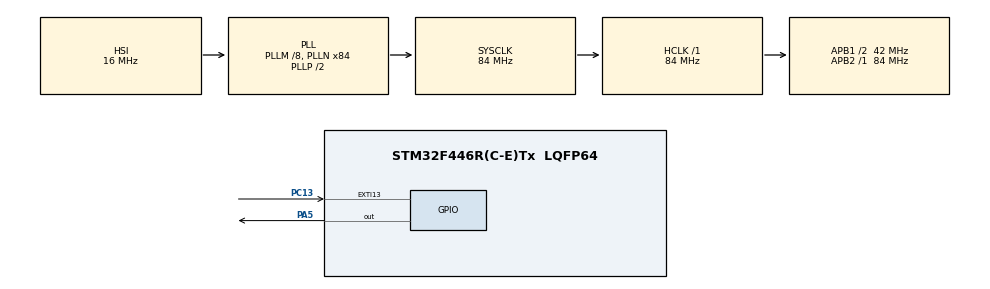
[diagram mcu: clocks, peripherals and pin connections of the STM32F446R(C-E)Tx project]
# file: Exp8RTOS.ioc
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FREERTOS.BinarySemaphores01=myBinarySem01,Dynamic,NULL,Available
FREERTOS.Tasks01=LED_Control,24,128,StartDefaultTask,Default,NULL,Dynamic,NULL,NULL
Mcu.Family=STM32F4
Mcu.Name=STM32F446R(C-E)Tx
Mcu.Package=LQFP64
NVIC.EXTI15_10_IRQn=true\:7\:0\:true\:false\:true\:true\:true\:true\:true
NVIC.PriorityGroup=NVIC_PRIORITYGROUP_4
NVIC.TIM6_DAC_IRQn=true\:15\:0\:false\:false\:true\:false\:false\:true\:true
NVIC.TimeBase=TIM6_DAC_IRQn
NVIC.TimeBaseIP=TIM6
PA13.Mode=Trace_Asynchronous_SW
PA13.Signal=SYS_JTMS-SWDIO
PA14.Mode=Trace_Asynchronous_SW
PA14.Signal=SYS_JTCK-SWCLK
PA5.Signal=GPIO_Output
PB3.Mode=Trace_Asynchronous_SW
PB3.Signal=SYS_JTDO-SWO
PC13.GPIO_ModeDefaultEXTI=GPIO_MODE_IT_FALLING
PC13.Signal=GPXTI13
ProjectManager.HeapSize=0x200
ProjectManager.StackSize=0x400
ProjectManager.TargetToolchain=STM32CubeIDE
RCC.AHBFreq_Value=84000000
RCC.APB1CLKDivider=RCC_HCLK_DIV2
RCC.APB1Freq_Value=42000000
RCC.APB1TimFreq_Value=84000000
RCC.APB2Freq_Value=84000000
RCC.APB2TimFreq_Value=84000000
RCC.CortexFreq_Value=84000000
RCC.HCLKFreq_Value=84000000
RCC.PLLM=8
RCC.PLLN=84
RCC.SYSCLKFreq_VALUE=84000000
RCC.SYSCLKSource=RCC_SYSCLKSOURCE_PLLCLK
RCC.USBFreq_Value=84000000
RCC.VCOOutputFreq_Value=168000000
VP_FREERTOS_VS_CMSIS_V2.Mode=CMSIS_V2
VP_SYS_VS_tim6.Mode=TIM6
board=custom

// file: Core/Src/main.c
/* USER CODE BEGIN Header */
/**
  ******************************************************************************
  * @file           : main.c
  * @brief          : Main program body
  ******************************************************************************
  */
/* USER CODE END Header */

#include "main.h"
#include "cmsis_os.h"

osThreadId_t LED_ControlHandle;
const osThreadAttr_t LED_Control_attributes = {
  .name = "LED_Control",
  .stack_size = 128 * 4,
  .priority = (osPriority_t) osPriorityNormal,
};

/* Definitions for myBinarySem01 */
osSemaphoreId_t myBinarySem01Handle;
const osSemaphoreAttr_t myBinarySem01_attributes = {
  .name = "myBinarySem01"
};

void SystemClock_Config(void);
static void MX_GPIO_Init(void);
void StartDefaultTask(void *argument);

/* USER CODE BEGIN 0 */
// Retarget fwrite to ITM
int _write(int file, char *ptr, int len) {
    for (int i = 0; i < len; i++) {
        ITM_SendChar(*ptr++);
    }
    return len;
}
/* USER CODE END 0 */

int main(void)
{

  HAL_Init();

  SystemClock_Config();

  MX_GPIO_Init();

  osKernelInitialize();

  /* Create the semaphores(s) */

  /* creation of myBinarySem01 */
  myBinarySem01Handle = osSemaphoreNew(1, 0, &myBinarySem01_attributes);   // FIXED HERE

  /* Create the thread(s) */

  /* creation of LED_Control */
  LED_ControlHandle = osThreadNew(StartDefaultTask, NULL, &LED_Control_attributes);

  osKernelStart();

  while (1)
  {
  }
}

void SystemClock_Config(void)
{
  RCC_OscInitTypeDef RCC_OscInitStruct = {0};
  RCC_ClkInitTypeDef RCC_ClkInitStruct = {0};

  __HAL_RCC_PWR_CLK_ENABLE();
  __HAL_PWR_VOLTAGESCALING_CONFIG(PWR_REGULATOR_VOLTAGE_SCALE3);

  RCC_OscInitStruct.OscillatorType = RCC_OSCILLATORTYPE_HSI;
  RCC_OscInitStruct.HSIState = RCC_HSI_ON;
  RCC_OscInitStruct.HSICalibrationValue = RCC_HSICALIBRATION_DEFAULT;

  RCC_OscInitStruct.PLL.PLLState = RCC_PLL_ON;
  RCC_OscInitStruct.PLL.PLLSource = RCC_PLLSOURCE_HSI;
  RCC_OscInitStruct.PLL.PLLM = 8;
  RCC_OscInitStruct.PLL.PLLN = 84;
  RCC_OscInitStruct.PLL.PLLP = RCC_PLLP_DIV2;
  RCC_OscInitStruct.PLL.PLLQ = 2;
  RCC_OscInitStruct.PLL.PLLR = 2;

  if (HAL_RCC_OscConfig(&RCC_OscInitStruct) != HAL_OK)
  {
    Error_Handler();
  }

  RCC_ClkInitStruct.ClockType = RCC_CLOCKTYPE_HCLK|RCC_CLOCKTYPE_SYSCLK
                              |RCC_CLOCKTYPE_PCLK1|RCC_CLOCKTYPE_PCLK2;

  RCC_ClkInitStruct.SYSCLKSource = RCC_SYSCLKSOURCE_PLLCLK;

  RCC_ClkInitStruct.AHBCLKDivider = RCC_SYSCLK_DIV1;

  RCC_ClkInitStruct.APB1CLKDivider = RCC_HCLK_DIV2;

  RCC_ClkInitStruct.APB2CLKDivider = RCC_HCLK_DIV1;

  if (HAL_RCC_ClockConfig(&RCC_ClkInitStruct, FLASH_LATENCY_2) != HAL_OK)
  {
    Error_Handler();
  }
}

static void MX_GPIO_Init(void)
{
  GPIO_InitTypeDef GPIO_InitStruct = {0};

  __HAL_RCC_GPIOC_CLK_ENABLE();
  __HAL_RCC_GPIOA_CLK_ENABLE();
  __HAL_RCC_GPIOB_CLK_ENABLE();

  HAL_GPIO_WritePin(GPIOA, GPIO_PIN_5, GPIO_PIN_RESET);

  GPIO_InitStruct.Pin = GPIO_PIN_13;
  GPIO_InitStruct.Mode = GPIO_MODE_IT_FALLING;
  GPIO_InitStruct.Pull = GPIO_NOPULL;
  HAL_GPIO_Init(GPIOC, &GPIO_InitStruct);

  GPIO_InitStruct.Pin = GPIO_PIN_5;
  GPIO_InitStruct.Mode = GPIO_MODE_OUTPUT_PP;
  GPIO_InitStruct.Pull = GPIO_NOPULL;
  GPIO_InitStruct.Speed = GPIO_SPEED_FREQ_LOW;
  HAL_GPIO_Init(GPIOA, &GPIO_InitStruct);

  HAL_NVIC_SetPriority(EXTI15_10_IRQn, 7, 0);
  HAL_NVIC_EnableIRQ(EXTI15_10_IRQn);
}

/* USER CODE BEGIN 4 */

void HAL_GPIO_EXTI_Callback(uint16_t GPIO_Pin){
	  osSemaphoreRelease(myBinarySem01Handle);
}

/* USER CODE END 4 */

void StartDefaultTask(void *argument)
{
	uint8_t i;

	for(;;)
	{
		  if (osSemaphoreAcquire(myBinarySem01Handle, 100) == osOK){
			  printf("Inside LEDControl Task\n");

			  i = 0;

			  while(i < 10){
				HAL_GPIO_TogglePin(GPIOA,GPIO_PIN_5);
				HAL_Delay(250);
				i = i + 1;
			  }
		  }
	}

	for(;;)
	{
	    osDelay(1);
	}
}

void HAL_TIM_PeriodElapsedCallback(TIM_HandleTypeDef *htim)
{
  if (htim->Instance == TIM6)
  {
    HAL_IncTick();
  }
}

void Error_Handler(void)
{
  __disable_irq();
  while (1)
  {
  }
}
